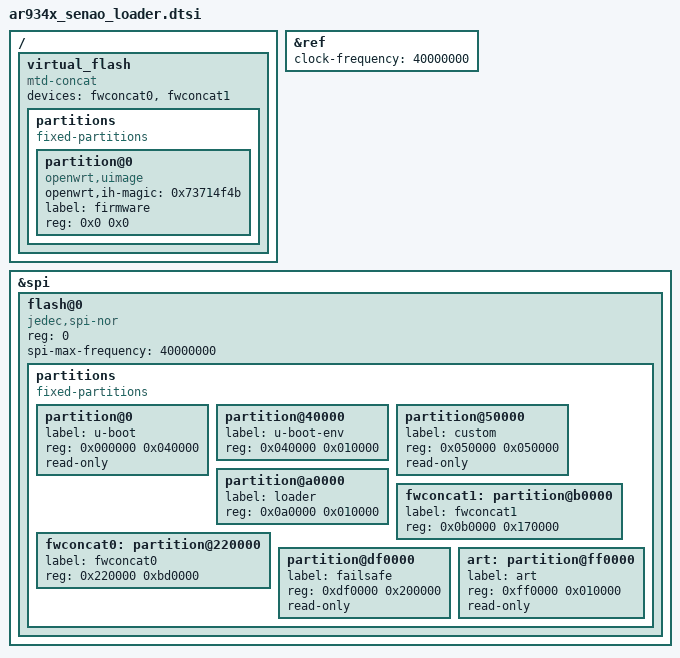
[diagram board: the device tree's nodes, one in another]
// SPDX-License-Identifier: GPL-2.0-or-later OR MIT

#include <dt-bindings/mtd/partitions/uimage.h>

/ {
	virtual_flash {
		compatible = "mtd-concat";

		devices = <&fwconcat0 &fwconcat1>;

		partitions {
			compatible = "fixed-partitions";
			#address-cells = <1>;
			#size-cells = <1>;

			partition@0 {
				compatible = "openwrt,uimage", "denx,uimage";
				openwrt,ih-magic = <0x73714f4b>;
				label = "firmware";
				reg = <0x0 0x0>;
			};
		};
	};
};

&ref {
	clock-frequency = <40000000>;
};

&spi {
	status = "okay";

	flash@0 {
		compatible = "jedec,spi-nor";
		reg = <0>;
		spi-max-frequency = <40000000>;

		partitions {
			compatible = "fixed-partitions";
			#address-cells = <1>;
			#size-cells = <1>;

			partition@0 {
				label = "u-boot";
				reg = <0x000000 0x040000>;
				read-only;
			};

			partition@40000 {
				label = "u-boot-env";
				reg = <0x040000 0x010000>;
			};

			partition@50000 {
				label = "custom";
				reg = <0x050000 0x050000>;
				read-only;
			};

			partition@a0000 {
				label = "loader";
				reg = <0x0a0000 0x010000>;
			};

			fwconcat1: partition@b0000 {
				label = "fwconcat1";
				reg = <0x0b0000 0x170000>;
			};

			fwconcat0: partition@220000 {
				label = "fwconcat0";
				reg = <0x220000 0xbd0000>;
			};

			partition@df0000 {
				label = "failsafe";
				reg = <0xdf0000 0x200000>;
				read-only;
			};

			art: partition@ff0000 {
				label = "art";
				reg = <0xff0000 0x010000>;
				read-only;
			};
		};
	};
};
